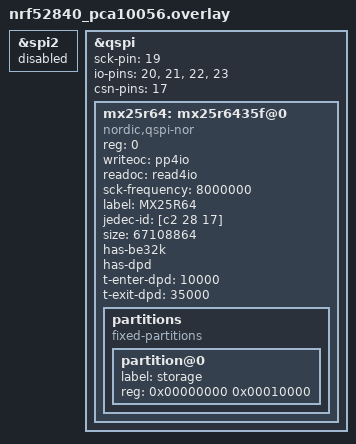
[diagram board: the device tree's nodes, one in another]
/*
 * Copyright (c) 2019 Peter Bigot Consulting, LLC
 * Copyright (c) 2019 Nordic Semiconductor ASA
 *
 * SPDX-License-Identifier: Apache-2.0
 */

&spi2 {
	status = "disabled";
};

/delete-node/ &storage_partition;
/delete-node/ &mx25r64;

&qspi {
	status = "okay";
	sck-pin = <19>;
	io-pins = <20>, <21>, <22>, <23>;
	csn-pins = <17>;
	mx25r64: mx25r6435f@0 {
		compatible = "nordic,qspi-nor";
		reg = <0>;
		writeoc = "pp4io";
		readoc = "read4io";
		sck-frequency = <8000000>;
		label = "MX25R64";
		jedec-id = [c2 28 17];
		size = <67108864>;
		has-be32k;
		has-dpd;
		t-enter-dpd = <10000>;
		t-exit-dpd = <35000>;
	};
};

&mx25r64 {
	partitions {
		compatible = "fixed-partitions";
		#address-cells = <1>;
		#size-cells = <1>;

		partition@0 {
			label = "storage";
			reg = <0x00000000 0x00010000>;
		};
	};
};
